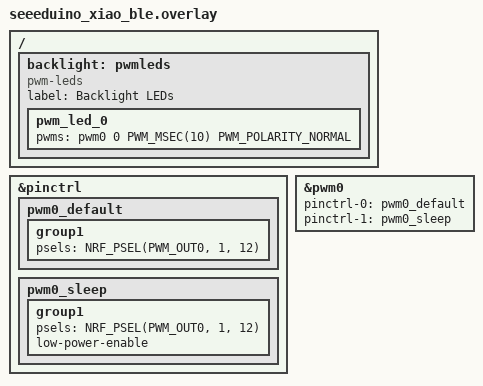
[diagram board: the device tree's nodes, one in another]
#include <zephyr/dt-bindings/pwm/pwm.h>

&pinctrl {
    pwm0_default: pwm0_default {
        group1 {
            psels = <NRF_PSEL(PWM_OUT0, 1, 12)>;
        };
    };

    pwm0_sleep: pwm0_sleep {
        group1 {
            psels = <NRF_PSEL(PWM_OUT0, 1, 12)>;
            low-power-enable;
        };
    };
};

/ {
    backlight: pwmleds {
        compatible = "pwm-leds";
        label = "Backlight LEDs";

        pwm_led_0: pwm_led_0 {
            pwms = <&pwm0 0 PWM_MSEC(10) PWM_POLARITY_NORMAL>;
        };
    };
};

&pwm0 {
    status = "okay";
    pinctrl-0 = <&pwm0_default>;
    pinctrl-1 = <&pwm0_sleep>;
    pinctrl-names = "default", "sleep";
};
